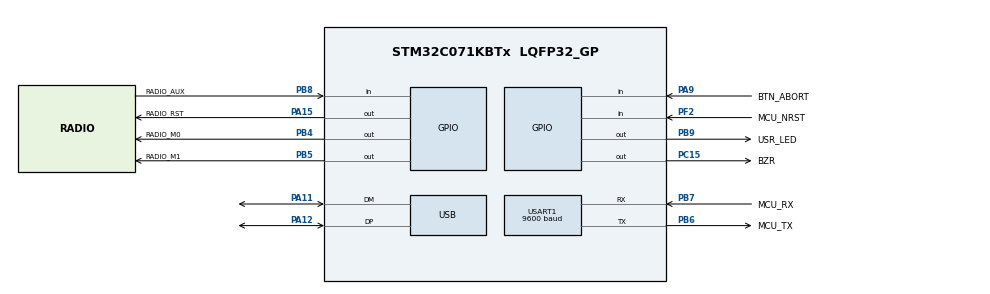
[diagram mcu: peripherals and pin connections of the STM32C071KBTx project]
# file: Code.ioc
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Mcu.Family=STM32C0
Mcu.Name=STM32C071KBTx
Mcu.Package=LQFP32_GP
NVIC.USB_DRD_FS_IRQn=true\:0\:0\:false\:false\:true\:true\:true\:true
PA11\ [PA9].Mode=Device
PA11\ [PA9].Signal=USB_DM
PA12\ [PA10].Mode=Device
PA12\ [PA10].Signal=USB_DP
PA13.Mode=Serial_Wire
PA13.Signal=DEBUG_SWDIO
PA14-BOOT0.Mode=Serial_Wire
PA14-BOOT0.Signal=DEBUG_SWCLK
PA15.GPIO_Label=RADIO_RST
PA15.Signal=GPIO_Output
PA9.GPIO_Label=BTN_ABORT
PA9.Signal=GPIO_Input
PB4.GPIO_Label=RADIO_M0
PB4.Signal=GPIO_Output
PB5.GPIO_Label=RADIO_M1
PB5.Signal=GPIO_Output
PB6.GPIO_Label=MCU_TX
PB6.GPIO_Speed=GPIO_SPEED_FREQ_VERY_HIGH
PB6.Mode=Asynchronous
PB6.Signal=USART1_TX
PB7.GPIO_Label=MCU_RX
PB7.GPIO_Speed=GPIO_SPEED_FREQ_VERY_HIGH
PB7.Mode=Asynchronous
PB7.Signal=USART1_RX
PB8.GPIO_Label=RADIO_AUX
PB8.Signal=GPIO_Input
PB9.GPIO_Label=USR_LED
PB9.Signal=GPIO_Output
PC15-OSCX_OUT(PC15).GPIO_Label=BZR
PC15-OSCX_OUT(PC15).Signal=GPIO_Output
PF2-NRST.GPIO_Label=MCU_NRST
PF2-NRST.Signal=GPIO_Input
ProjectManager.HeapSize=0x200
ProjectManager.StackSize=0x400
ProjectManager.TargetToolchain=CMake
RCC.ADCFreq_Value=48000000
RCC.AHBFreq_Value=48000000
RCC.CortexFreq_Value=48000000
RCC.EXTERNAL_CLOCK_VALUE=12288000
RCC.HCLKFreq_Value=48000000
RCC.HSE_VALUE=8000000
RCC.HSI48_VALUE=48000000
RCC.HSIKERCLKDivider=RCC_HSIKER_DIV5
RCC.HSISYSCLKDivider=RCC_HSI_DIV1
RCC.HSI_VALUE=48000000
RCC.LSE_VALUE=32768
RCC.SYSCLKFreq_VALUE=48000000
RCC.USART1CLockSelection=RCC_USART1CLKSOURCE_HSIKER
USART1.BaudRate=9600
USART1.DMADisableonRxErrorParam=ADVFEATURE_DMA_DISABLEONRXERROR
USART1.OverrunDisableParam=ADVFEATURE_OVERRUN_DISABLE
USART1.SwapParam=ADVFEATURE_SWAP_DISABLE
USART1.VirtualMode-Asynchronous=VM_ASYNC
USB.VirtualMode=Device_Only
board=custom

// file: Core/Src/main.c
/* USER CODE BEGIN Header */
/**
  ******************************************************************************
  * @file           : main.c
  * @brief          : Main program body
  ******************************************************************************
  * @attention
  *
  * Copyright (c) 2026 STMicroelectronics.
  * All rights reserved.
  *
  * This software is licensed under terms that can be found in the LICENSE file
  * in the root directory of this software component.
  * If no LICENSE file comes with this software, it is provided AS-IS.
  *
  ******************************************************************************
  */
/* USER CODE END Header */
#include "main.h"

UART_HandleTypeDef huart1;

PCD_HandleTypeDef hpcd_USB_DRD_FS;

void SystemClock_Config(void);
void PeriphCommonClock_Config(void);
static void MX_GPIO_Init(void);
static void MX_USART1_UART_Init(void);
static void MX_USB_PCD_Init(void);

int main(void)
{

  /* MCU Configuration--------------------------------------------------------*/

  /* Reset of all peripherals, Initializes the Flash interface and the Systick. */
  HAL_Init();

  /* Configure the system clock */
  SystemClock_Config();

  /* Initialize all configured peripherals */
  MX_GPIO_Init();
  MX_USART1_UART_Init();
  MX_USB_PCD_Init();
  /* USER CODE BEGIN 2 */

  // Init Code
  Init();

  /* USER CODE END 2 */

  /* Infinite loop */
  while (1)
  {

    /* USER CODE BEGIN 3 */

    // This is the main task
    Run();

  }
  /* USER CODE END 3 */
}

void SystemClock_Config(void)
{
  RCC_OscInitTypeDef RCC_OscInitStruct = {0};
  RCC_ClkInitTypeDef RCC_ClkInitStruct = {0};

  __HAL_FLASH_SET_LATENCY(FLASH_LATENCY_1);

  /** Initializes the RCC Oscillators according to the specified parameters
  * in the RCC_OscInitTypeDef structure.
  */
  RCC_OscInitStruct.OscillatorType = RCC_OSCILLATORTYPE_HSI|RCC_OSCILLATORTYPE_HSI48;
  RCC_OscInitStruct.HSIState = RCC_HSI_ON;
  RCC_OscInitStruct.HSIDiv = RCC_HSI_DIV1;
  RCC_OscInitStruct.HSICalibrationValue = RCC_HSICALIBRATION_DEFAULT;
  RCC_OscInitStruct.HSI48State = RCC_HSI48_ON;

  if (HAL_RCC_OscConfig(&RCC_OscInitStruct) != HAL_OK)
  {
    Error_Handler();
  }

  /** Initializes the CPU, AHB and APB buses clocks
  */
  RCC_ClkInitStruct.ClockType = RCC_CLOCKTYPE_HCLK|RCC_CLOCKTYPE_SYSCLK
                              |RCC_CLOCKTYPE_PCLK1;
  RCC_ClkInitStruct.SYSCLKSource = RCC_SYSCLKSOURCE_HSI;
  RCC_ClkInitStruct.SYSCLKDivider = RCC_SYSCLK_DIV1;
  RCC_ClkInitStruct.AHBCLKDivider = RCC_HCLK_DIV1;
  RCC_ClkInitStruct.APB1CLKDivider = RCC_APB1_DIV1;

  if (HAL_RCC_ClockConfig(&RCC_ClkInitStruct, FLASH_LATENCY_1) != HAL_OK)
  {
    Error_Handler();
  }
}

void PeriphCommonClock_Config(void)
{
  RCC_PeriphCLKInitTypeDef PeriphClkInit = {0};

  /** Initializes the common peripherals clocks
  */
  PeriphClkInit.PeriphClockSelection = RCC_PERIPHCLK_HSIKER;
  PeriphClkInit.HSIKerClockDivider = RCC_HSIKER_DIV5;

  if (HAL_RCCEx_PeriphCLKConfig(&PeriphClkInit) != HAL_OK)
  {
    Error_Handler();
  }
}

static void MX_USART1_UART_Init(void)
{

  huart1.Instance = USART1;
  huart1.Init.BaudRate = 9600;
  huart1.Init.WordLength = UART_WORDLENGTH_8B;
  huart1.Init.StopBits = UART_STOPBITS_1;
  huart1.Init.Parity = UART_PARITY_NONE;
  huart1.Init.Mode = UART_MODE_TX_RX;
  huart1.Init.HwFlowCtl = UART_HWCONTROL_NONE;
  huart1.Init.OverSampling = UART_OVERSAMPLING_16;
  huart1.Init.OneBitSampling = UART_ONE_BIT_SAMPLE_DISABLE;
  huart1.Init.ClockPrescaler = UART_PRESCALER_DIV1;
  huart1.AdvancedInit.AdvFeatureInit = UART_ADVFEATURE_RXOVERRUNDISABLE_INIT|UART_ADVFEATURE_DMADISABLEONERROR_INIT;
  huart1.AdvancedInit.OverrunDisable = UART_ADVFEATURE_OVERRUN_DISABLE;
  huart1.AdvancedInit.DMADisableonRxError = UART_ADVFEATURE_DMA_DISABLEONRXERROR;
  if (HAL_UART_Init(&huart1) != HAL_OK)
  {
    Error_Handler();
  }
  if (HAL_UARTEx_SetTxFifoThreshold(&huart1, UART_TXFIFO_THRESHOLD_1_8) != HAL_OK)
  {
    Error_Handler();
  }
  if (HAL_UARTEx_SetRxFifoThreshold(&huart1, UART_RXFIFO_THRESHOLD_1_8) != HAL_OK)
  {
    Error_Handler();
  }
  if (HAL_UARTEx_DisableFifoMode(&huart1) != HAL_OK)
  {
    Error_Handler();
  }

}

static void MX_USB_PCD_Init(void)
{

  hpcd_USB_DRD_FS.Instance = USB_DRD_FS;
  hpcd_USB_DRD_FS.Init.dev_endpoints = 8;
  hpcd_USB_DRD_FS.Init.speed = USBD_FS_SPEED;
  hpcd_USB_DRD_FS.Init.phy_itface = PCD_PHY_EMBEDDED;
  hpcd_USB_DRD_FS.Init.Sof_enable = DISABLE;
  hpcd_USB_DRD_FS.Init.low_power_enable = DISABLE;
  hpcd_USB_DRD_FS.Init.lpm_enable = DISABLE;
  hpcd_USB_DRD_FS.Init.battery_charging_enable = DISABLE;
  hpcd_USB_DRD_FS.Init.vbus_sensing_enable = DISABLE;
  hpcd_USB_DRD_FS.Init.bulk_doublebuffer_enable = DISABLE;
  hpcd_USB_DRD_FS.Init.iso_singlebuffer_enable = DISABLE;
  if (HAL_PCD_Init(&hpcd_USB_DRD_FS) != HAL_OK)
  {
    Error_Handler();
  }

}

static void MX_GPIO_Init(void)
{
  GPIO_InitTypeDef GPIO_InitStruct = {0};

  /* GPIO Ports Clock Enable */
  __HAL_RCC_GPIOB_CLK_ENABLE();
  __HAL_RCC_GPIOC_CLK_ENABLE();
  __HAL_RCC_GPIOF_CLK_ENABLE();
  __HAL_RCC_GPIOA_CLK_ENABLE();

  /*Configure GPIO pin Output Level */
  HAL_GPIO_WritePin(GPIOB, USR_LED_Pin|RADIO_M0_Pin|RADIO_M1_Pin, GPIO_PIN_RESET);

  /*Configure GPIO pin Output Level */
  HAL_GPIO_WritePin(BZR_GPIO_Port, BZR_Pin, GPIO_PIN_RESET);

  /*Configure GPIO pin Output Level */
  HAL_GPIO_WritePin(RADIO_RST_GPIO_Port, RADIO_RST_Pin, GPIO_PIN_RESET);

  /*Configure GPIO pins : USR_LED_Pin RADIO_M0_Pin RADIO_M1_Pin */
  GPIO_InitStruct.Pin = USR_LED_Pin|RADIO_M0_Pin|RADIO_M1_Pin;
  GPIO_InitStruct.Mode = GPIO_MODE_OUTPUT_PP;
  GPIO_InitStruct.Pull = GPIO_NOPULL;
  GPIO_InitStruct.Speed = GPIO_SPEED_FREQ_LOW;
  HAL_GPIO_Init(GPIOB, &GPIO_InitStruct);

  /*Configure GPIO pin : BZR_Pin */
  GPIO_InitStruct.Pin = BZR_Pin;
  GPIO_InitStruct.Mode = GPIO_MODE_OUTPUT_PP;
  GPIO_InitStruct.Pull = GPIO_NOPULL;
  GPIO_InitStruct.Speed = GPIO_SPEED_FREQ_LOW;
  HAL_GPIO_Init(BZR_GPIO_Port, &GPIO_InitStruct);

  /*Configure GPIO pin : MCU_NRST_Pin */
  GPIO_InitStruct.Pin = MCU_NRST_Pin;
  GPIO_InitStruct.Mode = GPIO_MODE_INPUT;
  GPIO_InitStruct.Pull = GPIO_NOPULL;
  HAL_GPIO_Init(MCU_NRST_GPIO_Port, &GPIO_InitStruct);

  /*Configure GPIO pin : BTN_ABORT_Pin */
  GPIO_InitStruct.Pin = BTN_ABORT_Pin;
  GPIO_InitStruct.Mode = GPIO_MODE_INPUT;
  GPIO_InitStruct.Pull = GPIO_NOPULL;
  HAL_GPIO_Init(BTN_ABORT_GPIO_Port, &GPIO_InitStruct);

  /*Configure GPIO pin : RADIO_RST_Pin */
  GPIO_InitStruct.Pin = RADIO_RST_Pin;
  GPIO_InitStruct.Mode = GPIO_MODE_OUTPUT_PP;
  GPIO_InitStruct.Pull = GPIO_NOPULL;
  GPIO_InitStruct.Speed = GPIO_SPEED_FREQ_LOW;
  HAL_GPIO_Init(RADIO_RST_GPIO_Port, &GPIO_InitStruct);

  /*Configure GPIO pin : RADIO_AUX_Pin */
  GPIO_InitStruct.Pin = RADIO_AUX_Pin;
  GPIO_InitStruct.Mode = GPIO_MODE_INPUT;
  GPIO_InitStruct.Pull = GPIO_NOPULL;
  HAL_GPIO_Init(RADIO_AUX_GPIO_Port, &GPIO_InitStruct);

}

void Error_Handler(void)
{
  __disable_irq();
  while (1)
  {
  }
}
